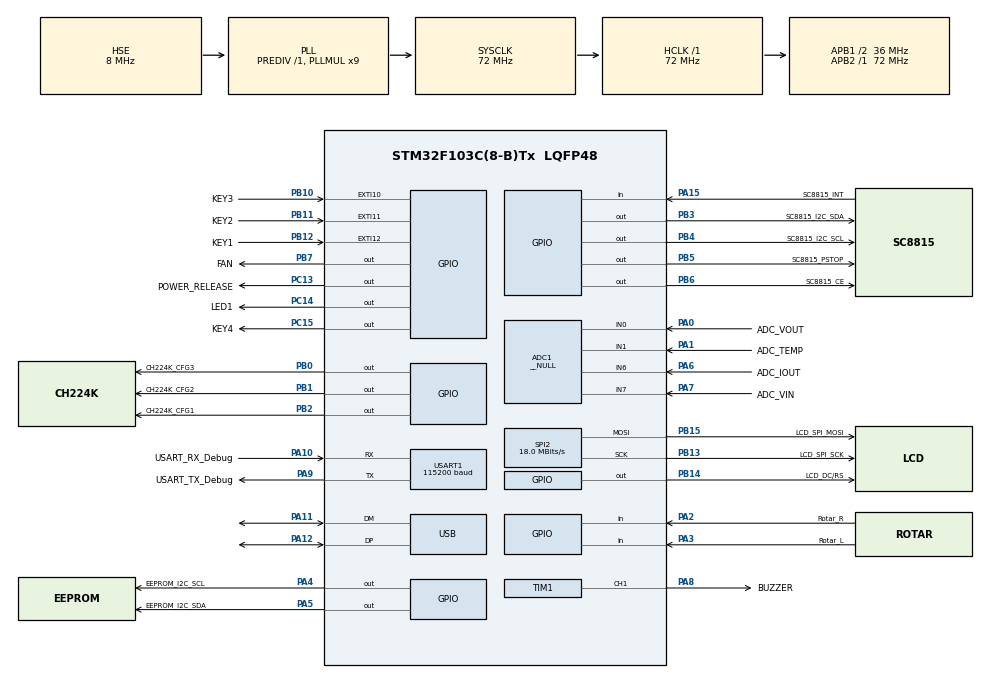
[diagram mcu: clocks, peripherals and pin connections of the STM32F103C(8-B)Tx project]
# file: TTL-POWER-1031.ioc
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ADC1.Channel-0\#ChannelRegularConversion=ADC_CHANNEL_0
ADC1.Channel-1\#ChannelRegularConversion=ADC_CHANNEL_1
ADC1.Channel-2\#ChannelRegularConversion=ADC_CHANNEL_6
ADC1.Channel-3\#ChannelRegularConversion=ADC_CHANNEL_7
ADC1.Channel-IN0=ADC_CHANNEL_0
ADC1.Channel-IN1=ADC_CHANNEL_1
ADC1.Channel-IN6=ADC_CHANNEL_6
ADC1.Channel-IN7=ADC_CHANNEL_7
ADC1.ContinuousConvMode=ENABLE
ADC1.DataAlign=ADC_DATAALIGN_RIGHT
ADC1.DiscontinuousConvMode=DISABLE
ADC1.EnableAnalogWatchDog=false
ADC1.EnableInjectedConversion=DISABLE
ADC1.EnableRegularConversion=ENABLE
ADC1.ExternalTrigConv=ADC_SOFTWARE_START
ADC1.Mode=__NULL
ADC1.NbrOfConversion=4
ADC1.Rank-0\#ChannelRegularConversion=1
ADC1.Rank-1\#ChannelRegularConversion=2
ADC1.Rank-2\#ChannelRegularConversion=3
ADC1.Rank-3\#ChannelRegularConversion=4
ADC1.SamplingTime-0\#ChannelRegularConversion=ADC_SAMPLETIME_239CYCLES_5
ADC1.SamplingTime-1\#ChannelRegularConversion=ADC_SAMPLETIME_239CYCLES_5
ADC1.SamplingTime-2\#ChannelRegularConversion=ADC_SAMPLETIME_239CYCLES_5
ADC1.SamplingTime-3\#ChannelRegularConversion=ADC_SAMPLETIME_239CYCLES_5
ADC1.ScanConvMode=ADC_SCAN_ENABLE
ADC1.master=1
Dma.ADC1.1.Direction=DMA_PERIPH_TO_MEMORY
Dma.ADC1.1.Instance=DMA1_Channel1
Dma.ADC1.1.MemDataAlignment=DMA_MDATAALIGN_HALFWORD
Dma.ADC1.1.MemInc=DMA_MINC_ENABLE
Dma.ADC1.1.Mode=DMA_CIRCULAR
Dma.ADC1.1.PeriphDataAlignment=DMA_PDATAALIGN_HALFWORD
Dma.ADC1.1.PeriphInc=DMA_PINC_DISABLE
Dma.ADC1.1.Priority=DMA_PRIORITY_HIGH
Dma.Request0=SPI2_TX
Dma.Request1=ADC1
Dma.SPI2_TX.0.Direction=DMA_MEMORY_TO_PERIPH
Dma.SPI2_TX.0.Instance=DMA1_Channel5
Dma.SPI2_TX.0.MemDataAlignment=DMA_MDATAALIGN_BYTE
Dma.SPI2_TX.0.MemInc=DMA_MINC_ENABLE
Dma.SPI2_TX.0.Mode=DMA_NORMAL
Dma.SPI2_TX.0.PeriphDataAlignment=DMA_PDATAALIGN_BYTE
Dma.SPI2_TX.0.PeriphInc=DMA_PINC_DISABLE
Dma.SPI2_TX.0.Priority=DMA_PRIORITY_VERY_HIGH
Mcu.Family=STM32F1
Mcu.Name=STM32F103C(8-B)Tx
Mcu.Package=LQFP48
NVIC.DMA1_Channel1_IRQn=true\:0\:0\:true\:false\:true\:false\:true\:true
NVIC.DMA1_Channel5_IRQn=true\:0\:0\:true\:false\:true\:false\:true\:true
NVIC.EXTI15_10_IRQn=true\:0\:0\:true\:false\:true\:true\:true\:true
NVIC.PriorityGroup=NVIC_PRIORITYGROUP_4
NVIC.TIM3_IRQn=true\:0\:0\:false\:false\:true\:true\:true\:true
NVIC.USART1_IRQn=true\:0\:0\:true\:false\:true\:true\:true\:true
NVIC.USB_LP_CAN1_RX0_IRQn=true\:0\:0\:false\:false\:true\:false\:true\:true
PA0-WKUP.GPIO_Label=ADC_VOUT
PA0-WKUP.Signal=ADCx_IN0
PA1.GPIO_Label=ADC_TEMP
PA1.Signal=ADCx_IN1
PA10.GPIO_Label=USART_RX_Debug
PA10.Mode=Asynchronous
PA10.Signal=USART1_RX
PA11.Mode=Device
PA11.Signal=USB_DM
PA12.Mode=Device
PA12.Signal=USB_DP
PA13.Mode=Serial_Wire
PA13.Signal=SYS_JTMS-SWDIO
PA14.Mode=Serial_Wire
PA14.Signal=SYS_JTCK-SWCLK
PA15.GPIO_Label=SC8815_INT
PA15.Signal=GPIO_Input
PA2.GPIO_Label=Rotar_R
PA2.Signal=GPIO_Input
PA3.GPIO_Label=Rotar_L
PA3.Signal=GPIO_Input
PA4.GPIO_Label=EEPROM_I2C_SCL
PA4.GPIO_ModeDefaultOutputPP=GPIO_MODE_OUTPUT_PP
PA4.GPIO_PuPd=GPIO_NOPULL
PA4.GPIO_Speed=GPIO_SPEED_FREQ_HIGH
PA4.Signal=GPIO_Output
PA5.GPIO_Label=EEPROM_I2C_SDA
PA5.GPIO_ModeDefaultOutputPP=GPIO_MODE_OUTPUT_PP
PA5.GPIO_PuPd=GPIO_NOPULL
PA5.GPIO_Speed=GPIO_SPEED_FREQ_HIGH
PA5.Signal=GPIO_Output
PA6.GPIO_Label=ADC_IOUT
PA6.Signal=ADCx_IN6
PA7.GPIO_Label=ADC_VIN
PA7.Signal=ADCx_IN7
PA8.GPIO_Label=BUZZER
PA8.Signal=S_TIM1_CH1
PA9.GPIO_Label=USART_TX_Debug
PA9.Mode=Asynchronous
PA9.Signal=USART1_TX
PB0.GPIO_Label=CH224K_CFG3
PB0.GPIO_Speed=GPIO_SPEED_FREQ_HIGH
PB0.PinState=GPIO_PIN_RESET
PB0.Signal=GPIO_Output
PB1.GPIO_Label=CH224K_CFG2
PB1.GPIO_Speed=GPIO_SPEED_FREQ_HIGH
PB1.Signal=GPIO_Output
PB10.GPIO_Label=KEY3
PB10.Signal=GPXTI10
PB11.GPIO_Label=KEY2
PB11.GPIO_ModeDefaultEXTI=GPIO_MODE_IT_FALLING
PB11.Signal=GPXTI11
PB12.GPIO_Label=KEY1
PB12.Signal=GPXTI12
PB13.GPIO_Label=LCD_SPI_SCK
PB13.Mode=TX_Only_Simplex_Unidirect_Master
PB13.Signal=SPI2_SCK
PB14.GPIO_Label=LCD_DC/RS
PB14.Signal=GPIO_Output
PB15.GPIO_Label=LCD_SPI_MOSI
PB15.Mode=TX_Only_Simplex_Unidirect_Master
PB15.Signal=SPI2_MOSI
PB2.GPIO_Label=CH224K_CFG1
PB2.GPIO_Speed=GPIO_SPEED_FREQ_HIGH
PB2.Signal=GPIO_Output
PB3.GPIO_Label=SC8815_I2C_SDA
PB3.GPIO_ModeDefaultOutputPP=GPIO_MODE_OUTPUT_OD
PB3.GPIO_PuPd=GPIO_NOPULL
PB3.GPIO_Speed=GPIO_SPEED_FREQ_HIGH
PB3.Signal=GPIO_Output
PB4.GPIO_Label=SC8815_I2C_SCL
PB4.GPIO_ModeDefaultOutputPP=GPIO_MODE_OUTPUT_OD
PB4.GPIO_PuPd=GPIO_NOPULL
PB4.GPIO_Speed=GPIO_SPEED_FREQ_HIGH
PB4.Signal=GPIO_Output
PB5.GPIO_Label=SC8815_PSTOP
PB5.Signal=GPIO_Output
PB6.GPIO_Label=SC8815_CE
PB6.Signal=GPIO_Output
PB7.GPIO_Label=FAN
PB7.Signal=GPIO_Output
PC13-TAMPER-RTC.GPIO_Label=POWER_RELEASE
PC13-TAMPER-RTC.GPIO_Speed=GPIO_SPEED_FREQ_HIGH
PC13-TAMPER-RTC.Signal=GPIO_Output
PC14-OSC32_IN.GPIO_Label=LED1
PC14-OSC32_IN.GPIO_Speed=GPIO_SPEED_FREQ_HIGH
PC14-OSC32_IN.PinState=GPIO_PIN_RESET
PC14-OSC32_IN.Signal=GPIO_Output
PC15-OSC32_OUT.GPIO_Label=KEY4
PC15-OSC32_OUT.GPIO_Speed=GPIO_SPEED_FREQ_HIGH
PC15-OSC32_OUT.Signal=GPIO_Output
PD0-OSC_IN.Mode=HSE-External-Oscillator
PD0-OSC_IN.Signal=RCC_OSC_IN
PD1-OSC_OUT.Mode=HSE-External-Oscillator
PD1-OSC_OUT.Signal=RCC_OSC_OUT
ProjectManager.HeapSize=0x200
ProjectManager.StackSize=0x400
ProjectManager.TargetToolchain=MDK-ARM V5.32
RCC.ADCPresc=RCC_ADCPCLK2_DIV6
RCC.AHBFreq_Value=72000000
RCC.APB1CLKDivider=RCC_HCLK_DIV2
RCC.APB1Freq_Value=36000000
RCC.APB1TimFreq_Value=72000000
RCC.APB2Freq_Value=72000000
RCC.APB2TimFreq_Value=72000000
RCC.FLatency=FLASH_LATENCY_2
RCC.HCLKFreq_Value=72000000
RCC.PLLMUL=RCC_PLL_MUL9
RCC.SYSCLKFreq_VALUE=72000000
RCC.SYSCLKSource=RCC_SYSCLKSOURCE_PLLCLK
RCC.USBFreq_Value=48000000
RCC.USBPrescaler=RCC_USBCLKSOURCE_PLL_DIV1_5
SH.ADCx_IN0.0=ADC1_IN0,IN0
SH.ADCx_IN1.0=ADC1_IN1,IN1
SH.ADCx_IN6.0=ADC1_IN6,IN6
SH.ADCx_IN7.0=ADC1_IN7,IN7
SH.S_TIM1_CH1.0=TIM1_CH1,PWM Generation1 CH1
SPI2.BaudRatePrescaler=SPI_BAUDRATEPRESCALER_2
SPI2.CLKPhase=SPI_PHASE_2EDGE
SPI2.CLKPolarity=SPI_POLARITY_HIGH
SPI2.CRCCalculation=SPI_CRCCALCULATION_DISABLE
SPI2.CalculateBaudRate=18.0 MBits/s
SPI2.DataSize=SPI_DATASIZE_8BIT
SPI2.Direction=SPI_DIRECTION_2LINES
SPI2.FirstBit=SPI_FIRSTBIT_MSB
SPI2.Mode=SPI_MODE_MASTER
SPI2.NSS=SPI_NSS_SOFT
SPI2.TIMode=SPI_TIMODE_DISABLE
SPI2.VirtualType=VM_MASTER
TIM1.AutoReloadPreload=TIM_AUTORELOAD_PRELOAD_DISABLE
TIM1.AutomaticOutput=TIM_AUTOMATICOUTPUT_DISABLE
TIM1.BreakPolarity=TIM_BREAKPOLARITY_HIGH
TIM1.BreakState=TIM_BREAK_DISABLE
TIM1.Channel-PWM\ Generation1\ CH1=TIM_CHANNEL_1
TIM1.ClockDivision=TIM_CLOCKDIVISION_DIV1
TIM1.CounterMode=TIM_COUNTERMODE_UP
TIM1.LockLevel=TIM_LOCKLEVEL_OFF
TIM1.OC1Preload_PWM=ENABLE
TIM1.OCFastMode_PWM-PWM\ Generation1\ CH1=TIM_OCFAST_DISABLE
TIM1.OCIdleState_1=TIM_OCIDLESTATE_RESET
TIM1.OCMode_PWM-PWM\ Generation1\ CH1=TIM_OCMODE_PWM1
TIM1.OCPolarity_1=TIM_OCPOLARITY_HIGH
TIM1.OffStateIDLEMode=TIM_OSSI_DISABLE
TIM1.OffStateRunMode=TIM_OSSR_DISABLE
TIM1.Period=999
TIM1.Prescaler=71
TIM1.Pulse-PWM\ Generation1\ CH1=500
TIM1.RepetitionCounter=0
TIM1.TIM_MasterOutputTrigger=TIM_TRGO_RESET
TIM1.TIM_MasterSlaveMode=TIM_MASTERSLAVEMODE_DISABLE
TIM2.AutoReloadPreload=TIM_AUTORELOAD_PRELOAD_ENABLE
TIM2.ClockDivision=TIM_CLOCKDIVISION_DIV1
TIM2.CounterMode=TIM_COUNTERMODE_DOWN
TIM2.Period=1
TIM2.Prescaler=7199
TIM2.TIM_MasterOutputTrigger=TIM_TRGO_RESET
TIM2.TIM_MasterSlaveMode=TIM_MASTERSLAVEMODE_DISABLE
TIM3.AutoReloadPreload=TIM_AUTORELOAD_PRELOAD_ENABLE
TIM3.ClockDivision=TIM_CLOCKDIVISION_DIV1
TIM3.CounterMode=TIM_COUNTERMODE_UP
TIM3.Period=99
TIM3.Prescaler=719
TIM3.TIM_MasterOutputTrigger=TIM_TRGO_RESET
TIM3.TIM_MasterSlaveMode=TIM_MASTERSLAVEMODE_DISABLE
USART1.BaudRate=115200
USART1.Mode=MODE_TX_RX
USART1.Parity=PARITY_NONE
USART1.StopBits=STOPBITS_1
USART1.VirtualMode=VM_ASYNC
USART1.WordLength=WORDLENGTH_8B
USB.DeviceSpeed=PCD_SPEED_FULL
USB.battery_charging_enable=DISABLE
USB.low_power_enable=DISABLE
USB.lpm_enable=DISABLE
USB_DEVICE.APP_RX_DATA_SIZE=1024
USB_DEVICE.APP_TX_DATA_SIZE=1024
USB_DEVICE.CLASS_NAME_FS=CDC
USB_DEVICE.CONFIGURATION_STRING_CDC_FS=CDC Config
USB_DEVICE.INTERFACE_STRING_CDC_FS=CDC Interface
USB_DEVICE.LANGID_STRING=1033
USB_DEVICE.MANUFACTURER_STRING=STMicroelectronics
USB_DEVICE.PID_CDC_FS=22336
USB_DEVICE.PRODUCT_STRING_CDC_FS=STM32 Virtual ComPort
USB_DEVICE.USBD_DEBUG_LEVEL=0
USB_DEVICE.USBD_MAX_NUM_CONFIGURATION=1
USB_DEVICE.USBD_MAX_NUM_INTERFACES=1
USB_DEVICE.USBD_MAX_STR_DESC_SIZ=512
USB_DEVICE.USBD_SELF_POWERED=1
USB_DEVICE.VID=1155
USB_DEVICE.VirtualMode=Cdc
USB_DEVICE.VirtualModeFS=Cdc_FS
VP_TIM2_VS_ClockSourceINT.Mode=Internal
VP_TIM3_VS_ClockSourceINT.Mode=Internal
VP_USB_DEVICE_VS_USB_DEVICE_CDC_FS.Mode=CDC_FS
board=custom

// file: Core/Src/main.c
/* USER CODE BEGIN Header */
/**
  ******************************************************************************
  * @file           : main.c
  * @brief          : Main program body
  ******************************************************************************
  * @attention
  *
  * Copyright (c) 2024 STMicroelectronics.
  * All rights reserved.
  *
  * This software is licensed under terms that can be found in the LICENSE file
  * in the root directory of this software component.
  * If no LICENSE file comes with this software, it is provided AS-IS.
  *
  ******************************************************************************
  */
/* USER CODE END Header */
#include "main.h"
#include "adc.h"
#include "dma.h"
#include "spi.h"
#include "tim.h"
#include "usart.h"
#include "usb_device.h"
#include "gpio.h"

/* USER CODE BEGIN Includes */
#include "Application.h"
#include "Application_Init.h"
/* USER CODE END Includes */

void SystemClock_Config(void);

int main(void)
{

  /* MCU Configuration--------------------------------------------------------*/

  /* Reset of all peripherals, Initializes the Flash interface and the Systick. */
  HAL_Init();

  /* Configure the system clock */
  SystemClock_Config();

  /* Initialize all configured peripherals */
  MX_GPIO_Init();
  MX_DMA_Init();
  MX_ADC1_Init();
  MX_SPI2_Init();
  MX_TIM1_Init();
  MX_USART1_UART_Init();
  MX_TIM2_Init();
  MX_USB_DEVICE_Init();
  MX_TIM3_Init();
  /* USER CODE BEGIN 2 */
  Application_Init();
  /* USER CODE END 2 */

  /* Infinite loop */
  /* USER CODE BEGIN WHILE */
  Application_main();
  while (1)
  {
    /* USER CODE END WHILE */

  }
}

void SystemClock_Config(void)
{
  RCC_OscInitTypeDef RCC_OscInitStruct = {0};
  RCC_ClkInitTypeDef RCC_ClkInitStruct = {0};
  RCC_PeriphCLKInitTypeDef PeriphClkInit = {0};

  /** Initializes the RCC Oscillators according to the specified parameters
  * in the RCC_OscInitTypeDef structure.
  */
  RCC_OscInitStruct.OscillatorType = RCC_OSCILLATORTYPE_HSE;
  RCC_OscInitStruct.HSEState = RCC_HSE_ON;
  RCC_OscInitStruct.HSEPredivValue = RCC_HSE_PREDIV_DIV1;
  RCC_OscInitStruct.HSIState = RCC_HSI_ON;
  RCC_OscInitStruct.PLL.PLLState = RCC_PLL_ON;
  RCC_OscInitStruct.PLL.PLLSource = RCC_PLLSOURCE_HSE;
  RCC_OscInitStruct.PLL.PLLMUL = RCC_PLL_MUL9;
  if (HAL_RCC_OscConfig(&RCC_OscInitStruct) != HAL_OK)
  {
    Error_Handler();
  }

  /** Initializes the CPU, AHB and APB buses clocks
  */
  RCC_ClkInitStruct.ClockType = RCC_CLOCKTYPE_HCLK|RCC_CLOCKTYPE_SYSCLK
                              |RCC_CLOCKTYPE_PCLK1|RCC_CLOCKTYPE_PCLK2;
  RCC_ClkInitStruct.SYSCLKSource = RCC_SYSCLKSOURCE_PLLCLK;
  RCC_ClkInitStruct.AHBCLKDivider = RCC_SYSCLK_DIV1;
  RCC_ClkInitStruct.APB1CLKDivider = RCC_HCLK_DIV2;
  RCC_ClkInitStruct.APB2CLKDivider = RCC_HCLK_DIV1;

  if (HAL_RCC_ClockConfig(&RCC_ClkInitStruct, FLASH_LATENCY_2) != HAL_OK)
  {
    Error_Handler();
  }
  PeriphClkInit.PeriphClockSelection = RCC_PERIPHCLK_ADC|RCC_PERIPHCLK_USB;
  PeriphClkInit.AdcClockSelection = RCC_ADCPCLK2_DIV6;
  PeriphClkInit.UsbClockSelection = RCC_USBCLKSOURCE_PLL_DIV1_5;
  if (HAL_RCCEx_PeriphCLKConfig(&PeriphClkInit) != HAL_OK)
  {
    Error_Handler();
  }
}

void Error_Handler(void)
{
  /* USER CODE BEGIN Error_Handler_Debug */
  /* User can add his own implementation to report the HAL error return state */
  __disable_irq();
  Application_Error_Handler();
  while (1)
  {
  }
  /* USER CODE END Error_Handler_Debug */
}

#ifdef  USE_FULL_ASSERT
/**
  * @brief  Reports the name of the source file and the source line number
  *         where the assert_param error has occurred.
  * @param  file: pointer to the source file name
  * @param  line: assert_param error line source number
  * @retval None
  */
void assert_failed(uint8_t *file, uint32_t line)
{
  /* USER CODE BEGIN 6 */
  /* User can add his own implementation to report the file name and line number,
     ex: printf("Wrong parameters value: file %s on line %d\r\n", file, line) */
  Application_Assert_Failed();
  /* USER CODE END 6 */
}
#endif /* USE_FULL_ASSERT */
